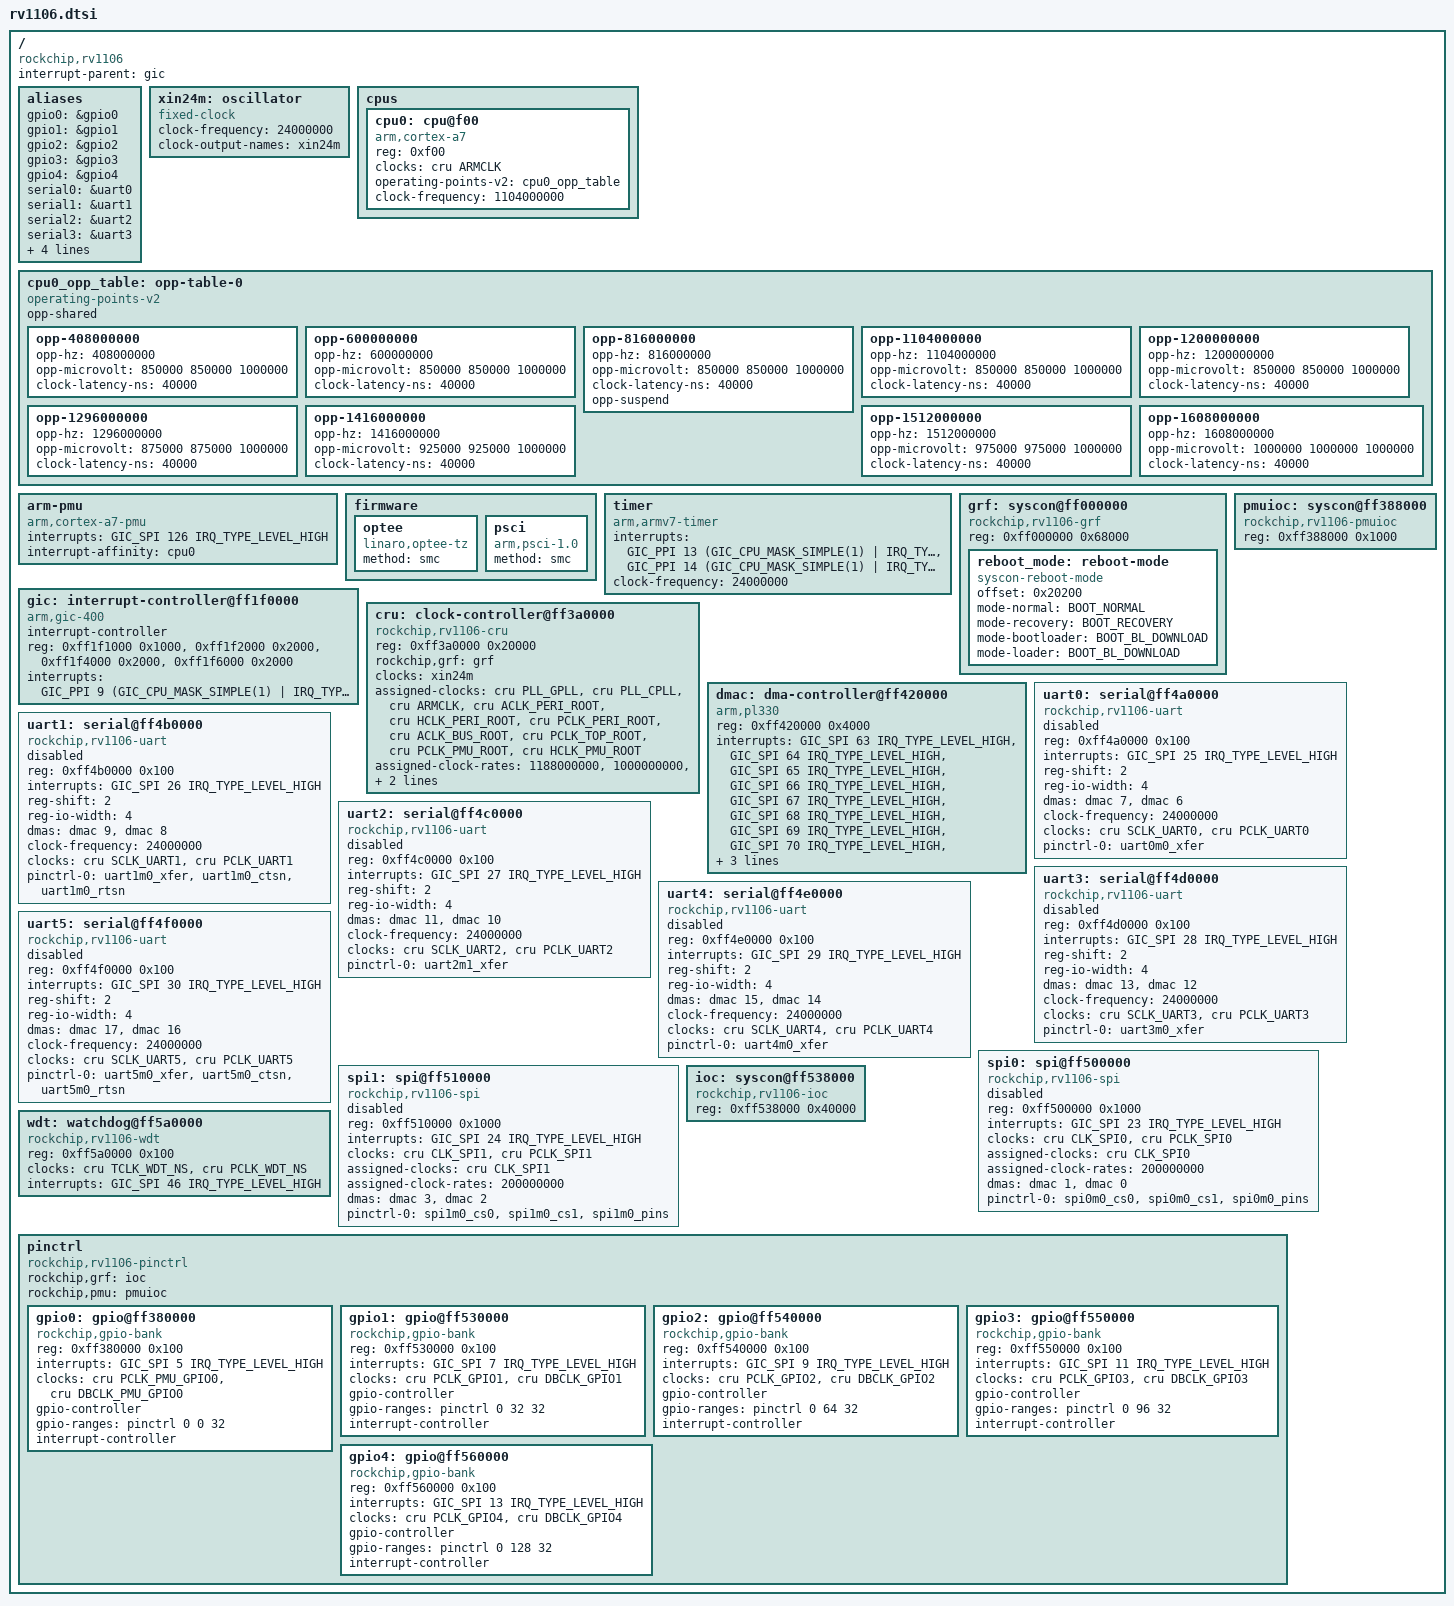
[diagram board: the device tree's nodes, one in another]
// SPDX-License-Identifier: (GPL-2.0+ OR MIT)
/*
 * Copyright (c) 2022 Rockchip Electronics Co., Ltd.
 */
#include <dt-bindings/clock/rv1106-cru.h>
#include <dt-bindings/gpio/gpio.h>
#include <dt-bindings/interrupt-controller/irq.h>
#include <dt-bindings/interrupt-controller/arm-gic.h>
#include <dt-bindings/pinctrl/rockchip.h>
#include <dt-bindings/soc/rockchip,boot-mode.h>

/ {
	#address-cells = <1>;
	#size-cells = <1>;

	compatible = "rockchip,rv1106";

	interrupt-parent = <&gic>;

	aliases {
		gpio0 = &gpio0;
		gpio1 = &gpio1;
		gpio2 = &gpio2;
		gpio3 = &gpio3;
		gpio4 = &gpio4;
		serial0 = &uart0;
		serial1 = &uart1;
		serial2 = &uart2;
		serial3 = &uart3;
		serial4 = &uart4;
		serial5 = &uart5;
		spi0 = &spi0;
		spi1 = &spi1;
	};

	xin24m: oscillator {
		compatible = "fixed-clock";
		clock-frequency = <24000000>;
		clock-output-names = "xin24m";
		#clock-cells = <0>;
	};

	cpus {
		#address-cells = <1>;
		#size-cells = <0>;

		cpu0: cpu@f00 {
			device_type = "cpu";
			compatible = "arm,cortex-a7";
			reg = <0xf00>;
			clocks = <&cru ARMCLK>;
			operating-points-v2 = <&cpu0_opp_table>;
			clock-frequency = <1104000000>;
		};
	};

	cpu0_opp_table: opp-table-0 {
		compatible = "operating-points-v2";
		opp-shared;

		opp-408000000 {
			opp-hz = /bits/ 64 <408000000>;
			opp-microvolt = <850000 850000 1000000>;
			clock-latency-ns = <40000>;
		};
		opp-600000000 {
			opp-hz = /bits/ 64 <600000000>;
			opp-microvolt = <850000 850000 1000000>;
			clock-latency-ns = <40000>;
		};
		opp-816000000 {
			opp-hz = /bits/ 64 <816000000>;
			opp-microvolt = <850000 850000 1000000>;
			clock-latency-ns = <40000>;
			opp-suspend;
		};
		opp-1104000000 {
			opp-hz = /bits/ 64 <1104000000>;
			opp-microvolt = <850000 850000 1000000>;
			clock-latency-ns = <40000>;
		};
		opp-1200000000 {
			opp-hz = /bits/ 64 <1200000000>;
			opp-microvolt = <850000 850000 1000000>;
			clock-latency-ns = <40000>;
		};
		opp-1296000000 {
			opp-hz = /bits/ 64 <1296000000>;
			opp-microvolt = <875000 875000 1000000>;
			clock-latency-ns = <40000>;
		};
		opp-1416000000 {
			opp-hz = /bits/ 64 <1416000000>;
			opp-microvolt = <925000 925000 1000000>;
			clock-latency-ns = <40000>;
		};
		opp-1512000000 {
			opp-hz = /bits/ 64 <1512000000>;
			opp-microvolt = <975000 975000 1000000>;
			clock-latency-ns = <40000>;
		};
		opp-1608000000 {
			opp-hz = /bits/ 64 <1608000000>;
			opp-microvolt = <1000000 1000000 1000000>;
			clock-latency-ns = <40000>;
		};
	};

	arm-pmu {
		compatible = "arm,cortex-a7-pmu";
		interrupts = <GIC_SPI 126 IRQ_TYPE_LEVEL_HIGH>;
		interrupt-affinity = <&cpu0>;
	};

	firmware {
		optee: optee {
			compatible = "linaro,optee-tz";
			method = "smc";
		};

		psci {
			compatible = "arm,psci-1.0";
			method = "smc";
		};
	};

	timer {
		compatible = "arm,armv7-timer";
		interrupts = <GIC_PPI 13 (GIC_CPU_MASK_SIMPLE(1) | IRQ_TYPE_LEVEL_HIGH)>,
			     <GIC_PPI 14 (GIC_CPU_MASK_SIMPLE(1) | IRQ_TYPE_LEVEL_HIGH)>;
		clock-frequency = <24000000>;
	};

	grf: syscon@ff000000 {
		compatible = "rockchip,rv1106-grf", "syscon", "simple-mfd";
		reg = <0xff000000 0x68000>;

		reboot_mode: reboot-mode {
			compatible = "syscon-reboot-mode";
			offset = <0x20200>;
			mode-normal = <BOOT_NORMAL>;
			mode-recovery = <BOOT_RECOVERY>;
			mode-bootloader = <BOOT_BL_DOWNLOAD>;
			mode-loader = <BOOT_BL_DOWNLOAD>;
		};
	};

	gic: interrupt-controller@ff1f0000 {
		compatible = "arm,gic-400";
		interrupt-controller;
		#interrupt-cells = <3>;
		#address-cells = <0>;

		reg = <0xff1f1000 0x1000>,
		      <0xff1f2000 0x2000>,
		      <0xff1f4000 0x2000>,
		      <0xff1f6000 0x2000>;
		interrupts = <GIC_PPI 9 (GIC_CPU_MASK_SIMPLE(1) | IRQ_TYPE_LEVEL_HIGH)>;
	};

	pmuioc: syscon@ff388000 {
		compatible = "rockchip,rv1106-pmuioc", "syscon";
		reg = <0xff388000 0x1000>;
	};

	cru: clock-controller@ff3a0000 {
		compatible = "rockchip,rv1106-cru";
		reg = <0xff3a0000 0x20000>;
		rockchip,grf = <&grf>;
		#clock-cells = <1>;
		#reset-cells = <1>;
		clocks = <&xin24m>;
		clock-names = "xin24m";

		assigned-clocks =
			<&cru PLL_GPLL>, <&cru PLL_CPLL>,
			<&cru ARMCLK>,
			<&cru ACLK_PERI_ROOT>, <&cru HCLK_PERI_ROOT>,
			<&cru PCLK_PERI_ROOT>, <&cru ACLK_BUS_ROOT>,
			<&cru PCLK_TOP_ROOT>, <&cru PCLK_PMU_ROOT>,
			<&cru HCLK_PMU_ROOT>;
		assigned-clock-rates =
			<1188000000>, <1000000000>,
			<1104000000>,
			<400000000>, <200000000>,
			<100000000>, <300000000>,
			<100000000>, <100000000>,
			<200000000>;
	};

	dmac: dma-controller@ff420000 {
		compatible = "arm,pl330", "arm,primecell";
		reg = <0xff420000 0x4000>;
		interrupts = <GIC_SPI 63 IRQ_TYPE_LEVEL_HIGH>,
			     <GIC_SPI 64 IRQ_TYPE_LEVEL_HIGH>,
			     <GIC_SPI 65 IRQ_TYPE_LEVEL_HIGH>,
			     <GIC_SPI 66 IRQ_TYPE_LEVEL_HIGH>,
			     <GIC_SPI 67 IRQ_TYPE_LEVEL_HIGH>,
			     <GIC_SPI 68 IRQ_TYPE_LEVEL_HIGH>,
			     <GIC_SPI 69 IRQ_TYPE_LEVEL_HIGH>,
			     <GIC_SPI 70 IRQ_TYPE_LEVEL_HIGH>,
			     <GIC_SPI 79 IRQ_TYPE_LEVEL_HIGH>;
		#dma-cells = <1>;
		clocks = <&cru ACLK_DMAC>;
		clock-names = "apb_pclk";
		arm,pl330-periph-burst;
	};

	uart0: serial@ff4a0000 {
		compatible = "rockchip,rv1106-uart", "snps,dw-apb-uart";
		reg = <0xff4a0000 0x100>;
		interrupts = <GIC_SPI 25 IRQ_TYPE_LEVEL_HIGH>;
		reg-shift = <2>;
		reg-io-width = <4>;
		dmas = <&dmac 7>, <&dmac 6>;
		clock-frequency = <24000000>;
		clocks = <&cru SCLK_UART0>, <&cru PCLK_UART0>;
		clock-names = "baudclk", "apb_pclk";
		pinctrl-names = "default";
		pinctrl-0 = <&uart0m0_xfer>;
		status = "disabled";
	};

	uart1: serial@ff4b0000 {
		compatible = "rockchip,rv1106-uart", "snps,dw-apb-uart";
		reg = <0xff4b0000 0x100>;
		interrupts = <GIC_SPI 26 IRQ_TYPE_LEVEL_HIGH>;
		reg-shift = <2>;
		reg-io-width = <4>;
		dmas = <&dmac 9>, <&dmac 8>;
		clock-frequency = <24000000>;
		clocks = <&cru SCLK_UART1>, <&cru PCLK_UART1>;
		clock-names = "baudclk", "apb_pclk";
		pinctrl-names = "default";
		pinctrl-0 = <&uart1m0_xfer &uart1m0_ctsn &uart1m0_rtsn>;
		status = "disabled";
	};

	uart2: serial@ff4c0000 {
		compatible = "rockchip,rv1106-uart", "snps,dw-apb-uart";
		reg = <0xff4c0000 0x100>;
		interrupts = <GIC_SPI 27 IRQ_TYPE_LEVEL_HIGH>;
		reg-shift = <2>;
		reg-io-width = <4>;
		dmas = <&dmac 11>, <&dmac 10>;
		clock-frequency = <24000000>;
		clocks = <&cru SCLK_UART2>, <&cru PCLK_UART2>;
		clock-names = "baudclk", "apb_pclk";
		pinctrl-names = "default";
		pinctrl-0 = <&uart2m1_xfer>;
		status = "disabled";
	};

	uart3: serial@ff4d0000 {
		compatible = "rockchip,rv1106-uart", "snps,dw-apb-uart";
		reg = <0xff4d0000 0x100>;
		interrupts = <GIC_SPI 28 IRQ_TYPE_LEVEL_HIGH>;
		reg-shift = <2>;
		reg-io-width = <4>;
		dmas = <&dmac 13>, <&dmac 12>;
		clock-frequency = <24000000>;
		clocks = <&cru SCLK_UART3>, <&cru PCLK_UART3>;
		clock-names = "baudclk", "apb_pclk";
		pinctrl-names = "default";
		pinctrl-0 = <&uart3m0_xfer>;
		status = "disabled";
	};

	uart4: serial@ff4e0000 {
		compatible = "rockchip,rv1106-uart", "snps,dw-apb-uart";
		reg = <0xff4e0000 0x100>;
		interrupts = <GIC_SPI 29 IRQ_TYPE_LEVEL_HIGH>;
		reg-shift = <2>;
		reg-io-width = <4>;
		dmas = <&dmac 15>, <&dmac 14>;
		clock-frequency = <24000000>;
		clocks = <&cru SCLK_UART4>, <&cru PCLK_UART4>;
		clock-names = "baudclk", "apb_pclk";
		pinctrl-names = "default";
		pinctrl-0 = <&uart4m0_xfer>;
		status = "disabled";
	};

	uart5: serial@ff4f0000 {
		compatible = "rockchip,rv1106-uart", "snps,dw-apb-uart";
		reg = <0xff4f0000 0x100>;
		interrupts = <GIC_SPI 30 IRQ_TYPE_LEVEL_HIGH>;
		reg-shift = <2>;
		reg-io-width = <4>;
		dmas = <&dmac 17>, <&dmac 16>;
		clock-frequency = <24000000>;
		clocks = <&cru SCLK_UART5>, <&cru PCLK_UART5>;
		clock-names = "baudclk", "apb_pclk";
		pinctrl-names = "default";
		pinctrl-0 = <&uart5m0_xfer &uart5m0_ctsn &uart5m0_rtsn>;
		status = "disabled";
	};

	spi0: spi@ff500000 {
		compatible = "rockchip,rv1106-spi", "rockchip,rk3066-spi";
		reg = <0xff500000 0x1000>;
		interrupts = <GIC_SPI 23 IRQ_TYPE_LEVEL_HIGH>;
		#address-cells = <1>;
		#size-cells = <0>;
		clocks = <&cru CLK_SPI0>, <&cru PCLK_SPI0>;
		clock-names = "spiclk", "apb_pclk";
		assigned-clocks = <&cru CLK_SPI0>;
		assigned-clock-rates = <200000000>;
		dmas = <&dmac 1>, <&dmac 0>;
		dma-names = "tx", "rx";
		pinctrl-names = "default";
		pinctrl-0 = <&spi0m0_cs0 &spi0m0_cs1 &spi0m0_pins>;
		status = "disabled";
	};

	spi1: spi@ff510000 {
		compatible = "rockchip,rv1106-spi", "rockchip,rk3066-spi";
		reg = <0xff510000 0x1000>;
		interrupts = <GIC_SPI 24 IRQ_TYPE_LEVEL_HIGH>;
		#address-cells = <1>;
		#size-cells = <0>;
		clocks = <&cru CLK_SPI1>, <&cru PCLK_SPI1>;
		clock-names = "spiclk", "apb_pclk";
		assigned-clocks = <&cru CLK_SPI1>;
		assigned-clock-rates = <200000000>;
		dmas = <&dmac 3>, <&dmac 2>;
		dma-names = "tx", "rx";
		pinctrl-names = "default";
		pinctrl-0 = <&spi1m0_cs0 &spi1m0_cs1 &spi1m0_pins>;
		status = "disabled";
	};

	ioc: syscon@ff538000 {
		compatible = "rockchip,rv1106-ioc", "syscon";
		reg = <0xff538000 0x40000>;
	};

	wdt: watchdog@ff5a0000 {
		compatible = "rockchip,rv1106-wdt", "snps,dw-wdt";
		reg = <0xff5a0000 0x100>;
		clocks = <&cru TCLK_WDT_NS>, <&cru PCLK_WDT_NS>;
		clock-names = "tclk", "pclk";
		interrupts = <GIC_SPI 46 IRQ_TYPE_LEVEL_HIGH>;
	};

	pinctrl: pinctrl {
		compatible = "rockchip,rv1106-pinctrl";
		rockchip,grf = <&ioc>;
		rockchip,pmu = <&pmuioc>;
		#address-cells = <1>;
		#size-cells = <1>;
		ranges;

		gpio0: gpio@ff380000 {
			compatible = "rockchip,gpio-bank";
			reg = <0xff380000 0x100>;
			interrupts = <GIC_SPI 5 IRQ_TYPE_LEVEL_HIGH>;
			clocks = <&cru PCLK_PMU_GPIO0>, <&cru DBCLK_PMU_GPIO0>;

			gpio-controller;
			#gpio-cells = <2>;
			gpio-ranges = <&pinctrl 0 0 32>;
			interrupt-controller;
			#interrupt-cells = <2>;
		};

		gpio1: gpio@ff530000 {
			compatible = "rockchip,gpio-bank";
			reg = <0xff530000 0x100>;
			interrupts = <GIC_SPI 7 IRQ_TYPE_LEVEL_HIGH>;
			clocks = <&cru PCLK_GPIO1>, <&cru DBCLK_GPIO1>;

			gpio-controller;
			#gpio-cells = <2>;
			gpio-ranges = <&pinctrl 0 32 32>;
			interrupt-controller;
			#interrupt-cells = <2>;
		};

		gpio2: gpio@ff540000 {
			compatible = "rockchip,gpio-bank";
			reg = <0xff540000 0x100>;
			interrupts = <GIC_SPI 9 IRQ_TYPE_LEVEL_HIGH>;
			clocks = <&cru PCLK_GPIO2>, <&cru DBCLK_GPIO2>;

			gpio-controller;
			#gpio-cells = <2>;
			gpio-ranges = <&pinctrl 0 64 32>;
			interrupt-controller;
			#interrupt-cells = <2>;
		};

		gpio3: gpio@ff550000 {
			compatible = "rockchip,gpio-bank";
			reg = <0xff550000 0x100>;
			interrupts = <GIC_SPI 11 IRQ_TYPE_LEVEL_HIGH>;
			clocks = <&cru PCLK_GPIO3>, <&cru DBCLK_GPIO3>;

			gpio-controller;
			#gpio-cells = <2>;
			gpio-ranges = <&pinctrl 0 96 32>;
			interrupt-controller;
			#interrupt-cells = <2>;
		};

		gpio4: gpio@ff560000 {
			compatible = "rockchip,gpio-bank";
			reg = <0xff560000 0x100>;
			interrupts = <GIC_SPI 13 IRQ_TYPE_LEVEL_HIGH>;
			clocks = <&cru PCLK_GPIO4>, <&cru DBCLK_GPIO4>;

			gpio-controller;
			#gpio-cells = <2>;
			gpio-ranges = <&pinctrl 0 128 32>;
			interrupt-controller;
			#interrupt-cells = <2>;
		};
	};
};

#include "rv1106-pinctrl.dtsi"
